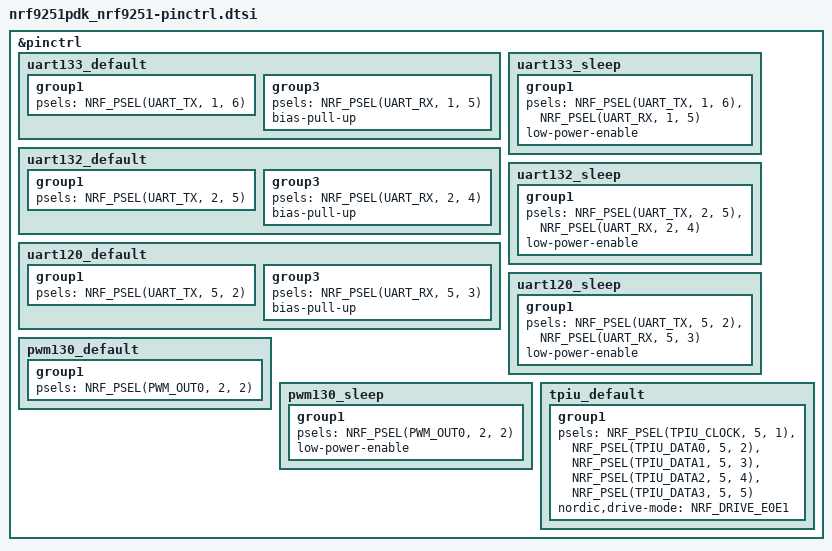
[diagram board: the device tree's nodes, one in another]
/*
 * Copyright (c) 2026 Nordic Semiconductor ASA
 *
 * SPDX-License-Identifier: Apache-2.0
 */

&pinctrl {
	/omit-if-no-ref/ uart133_default: uart133_default {
		group1 {
			psels = <NRF_PSEL(UART_TX, 1, 6)>;
		};
		group3 {
			psels = <NRF_PSEL(UART_RX, 1, 5)>;
			bias-pull-up;
		};
	};

	/omit-if-no-ref/ uart133_sleep: uart133_sleep {
		group1 {
			psels = <NRF_PSEL(UART_TX, 1, 6)>,
				    <NRF_PSEL(UART_RX, 1, 5)>;
			low-power-enable;
		};
	};

	/omit-if-no-ref/ uart132_default: uart132_default {
		group1 {
			psels = <NRF_PSEL(UART_TX, 2, 5)>;
		};
		group3 {
			psels = <NRF_PSEL(UART_RX, 2, 4)>;
			bias-pull-up;
		};
	};

	/omit-if-no-ref/ uart132_sleep: uart132_sleep {
		group1 {
			psels = <NRF_PSEL(UART_TX, 2, 5)>,
				    <NRF_PSEL(UART_RX, 2, 4)>;
			low-power-enable;
		};
	};

	/omit-if-no-ref/ uart120_default: uart120_default {
		group1 {
			psels = <NRF_PSEL(UART_TX, 5, 2)>;
		};
		group3 {
			psels = <NRF_PSEL(UART_RX, 5, 3)>;
			bias-pull-up;
		};
	};

	/omit-if-no-ref/ uart120_sleep: uart120_sleep {
		group1 {
			psels = <NRF_PSEL(UART_TX, 5, 2)>,
				    <NRF_PSEL(UART_RX, 5, 3)>;
			low-power-enable;
		};
	};

	/omit-if-no-ref/ pwm130_default: pwm130_default {
		group1 {
			psels = <NRF_PSEL(PWM_OUT0, 2, 2)>;
		};
	};

	/omit-if-no-ref/ pwm130_sleep: pwm130_sleep {
		group1 {
			psels = <NRF_PSEL(PWM_OUT0, 2, 2)>;
			low-power-enable;
		};
	};

	/omit-if-no-ref/ tpiu_default: tpiu_default {
		group1 {
			psels = <NRF_PSEL(TPIU_CLOCK, 5, 1)>,
				<NRF_PSEL(TPIU_DATA0, 5, 2)>,
				<NRF_PSEL(TPIU_DATA1, 5, 3)>,
				<NRF_PSEL(TPIU_DATA2, 5, 4)>,
				<NRF_PSEL(TPIU_DATA3, 5, 5)>;
			nordic,drive-mode = <NRF_DRIVE_E0E1>;
		};
	};
};
